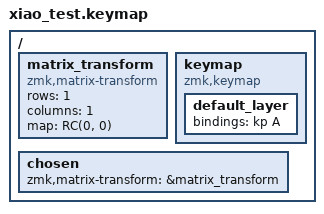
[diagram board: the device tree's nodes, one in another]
#include <behaviors.dtsi>
#include <dt-bindings/zmk/keys.h>
#include <dt-bindings/zmk/matrix_transform.h>

/ {
    matrix_transform: matrix_transform {
        compatible = "zmk,matrix-transform";

        rows = <1>;
        columns = <1>;

        map = <
            RC(0, 0)
        >;
    };

    keymap {
        compatible = "zmk,keymap";

        default_layer {
            bindings = <&kp A>;
        };
    };

    chosen {
        zmk,matrix-transform = &matrix_transform;
    };
};
